# MB9BF51xS register map
File version: 1.8
CPU: 
Registers are 16-bit, read-write, reset 0x0 unless marked. A register's access mark holds for its fields unless they carry their own. Offsets are from the block's base; [hi:lo] are bit positions; {n}, {i} and the like mark numbered series.

## QPRC0 — Quadrature Position/Revolution Counter 0
Base 0x40026000
Same registers: QPRC1 0x40026040, QPRC2 0x40026080
0x00 QPCR — QPRC Position Count Register
0x04 QRCR — QPRC Revolution Count Register
0x08 QPCCR — QPRC Position Counter Compare Register
0x0C QPRCR — QPRC Position and Revolution Counter Compare Register
0x10 QMPR reset 0xFFFF — QPRC Maximum Position Register
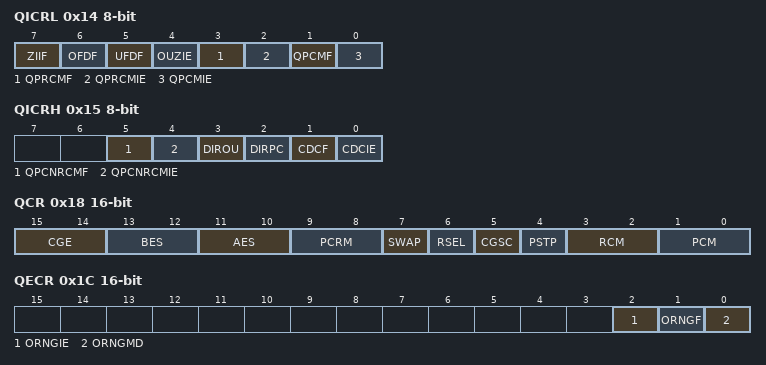
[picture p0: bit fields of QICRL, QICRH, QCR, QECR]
0x14 QICRL 8-bit — Low-Order Bytes of QPRC Interrupt Control Register
  [7] ZIIF — Zero index interrupt request flag bit
  [6] OFDF — Overflow interrupt request flag bit
  [5] UFDF — Underflow interrupt request flag bit
  [4] OUZIE — "Overflow, underflow, or zero index interrupt enable bit"
  [3] QPRCMF — PC and RC match interrupt request flag bit
  [2] QPRCMIE — PC and RC match interrupt enable bit
  [1] QPCMF — PC match interrupt request flag bit
  [0] QPCMIE — PC match interrupt enable bit
0x15 QICRH 8-bit — High-Order Bytes of QPRC Interrupt Control Register
  [5] QPCNRCMF — PC match and RC match interrupt request flag bit
  [4] QPCNRCMIE — PC match and RC match interrupt enable bit
  [3] DIROU ro — Last position counter flow direction bit
  [2] DIRPC ro — Last position counter direction bit
  [1] CDCF — Count inversion interrupt request flag bit
  [0] CDCIE — Count inversion interrupt enable bit
0x18 QCR — QPRC Control Register
  [15:14] CGE — Detection edge selection bits
  [13:12] BES — BIN detection edge selection bits
  [11:10] AES — AIN detection edge selection bits
  [9:8] PCRM — Position counter reset mask bits
  [7] SWAP — Swap bit
  [6] RSEL — Register function selection bit
  [5] CGSC — Count clear or gate selection bit
  [4] PSTP — Position counter stop bit
  [3:2] RCM — Revolution counter mode bits
  [1:0] PCM — Position counter mode bits
0x1C QECR — QPRC Extension Control Register
  [2] ORNGIE — Outrange interrupt enable bit
  [1] ORNGF — Outrange interrupt request flag bit
  [0] ORNGMD — Outrange mode selection bit
0x3C QRCRR — Quad counter rotation count Register
0x3E QPCRR — Quad counter position count Register

## WC — Watch Counter
Base 0x4003A000
0x00 WCRD 8-bit ro — Watch Counter Read Register
  [5:0] CTR — counter value
0x01 WCRL 8-bit — Watch Counter Reload Register
  [5:0] RLC — reload value
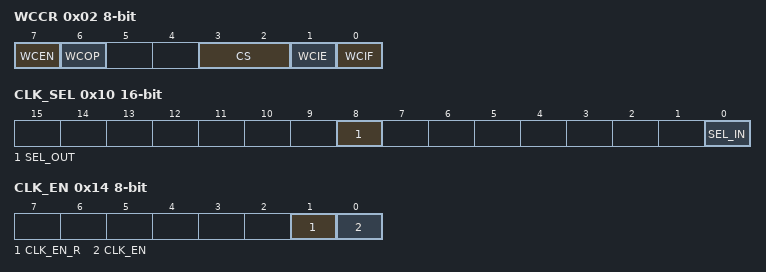
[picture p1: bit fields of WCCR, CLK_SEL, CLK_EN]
0x02 WCCR 8-bit — Watch Counter Control Register
  [7] WCEN — Watch counter operation enable bit
  [6] WCOP ro — Watch counter operating state flag
  [3:2] CS — Count clock select bits
  [1] WCIE — Interrupt request enable bit
  [0] WCIF — Interrupt request flag bit
0x10 CLK_SEL — Clock Selection Register
  [8] SEL_OUT — Output clock selection bit
  [0] SEL_IN — Input clock selection bit
0x14 CLK_EN 8-bit — Division Clock Enable Register
  [1] CLK_EN_R — Division clock enable read bit
  [0] CLK_EN — Division clock enable bit

## EXTI — External Interrupt and NMI Control
Base 0x40030000
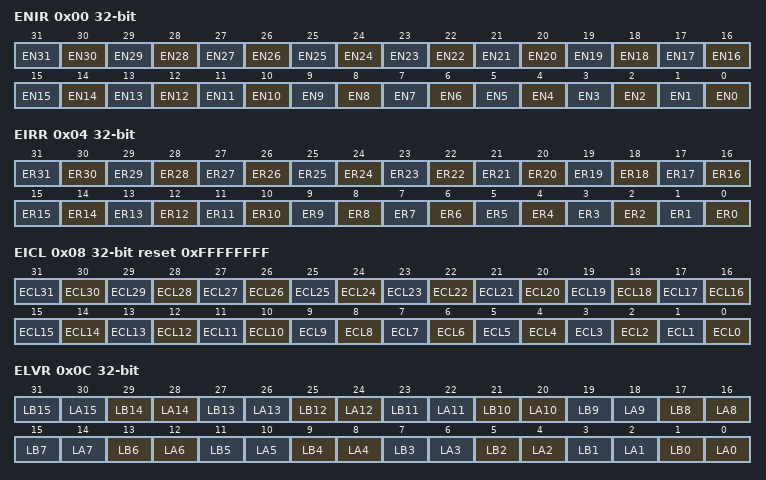
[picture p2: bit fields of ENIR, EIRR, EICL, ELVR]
0x00 ENIR 32-bit — Enable Interrupt Request Register
  [n] EN{n} (n=0..31) — Bit{n} of ENIR
0x04 EIRR 32-bit ro reset not defined — External Interrupt Request Register
  [n] ER{n} (n=0..31) — Bit{n} of EIRR
0x08 EICL 32-bit reset 0xFFFFFFFF — External Interrupt Clear Register
  [n] ECL{n} (n=0..31) — Bit{n} of EICL
0x0C ELVR 32-bit — External Interrupt Level Register
  [2n+1] LB{n} (n=0..15) — Bit{2n+1} of ELVR
  [2n] LA{n} (n=0..15) — Bit{2n} of ELVR
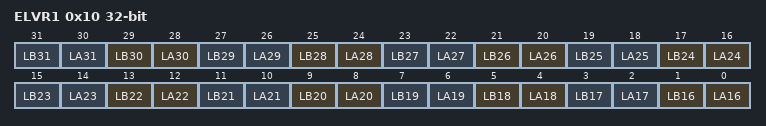
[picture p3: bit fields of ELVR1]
0x10 ELVR1 32-bit — External Interrupt Level Register 1
  [2n-31] LB{n} (n=16..31) — Bit{2n-31} of ELVR1
  [2n-32] LA{n} (n=16..31) — Bit{2n-32} of ELVR1
0x14 NMIRR 8-bit ro — Non Maskable Interrupt Request Register
  [0] NR — NMI interrupt request detection bit
0x18 NMICL 8-bit reset 0x1 — Non Maskable Interrupt Clear Register
  [0] NCL — NMI interrupt cause clear bit

## LVD — Low-voltage Detection
Base 0x40035000
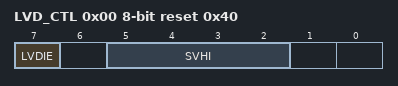
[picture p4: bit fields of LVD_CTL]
0x00 LVD_CTL 8-bit reset 0x40 — Low-voltage Detection Voltage Control Register
  [7] LVDIE — Low-voltage detection interrupt enable bit
  [5:2] SVHI — Low-voltage detection interrupt voltage setting bits
0x04 LVD_STR 8-bit ro — Low-voltage Detection Interrupt Register
  [7] LVDIR — Low-voltage detection interrupt bit
0x08 LVD_CLR 8-bit reset 0x80 — Low-voltage Detection Interrupt Clear Register
  [7] LVDCL — Low-voltage detection interrupt clear bit
0x0C LVD_RLR 32-bit reset 0x1 — Low-voltage Detection Voltage Protection Register
  [31:0] LVDLCK — Low-voltage Detection Voltage Control Register protection bits
0x10 LVD_STR2 8-bit ro reset 0x40 — Low-voltage Detection Circuit Status Register
  [7] LVDIRDY — Low-voltage detection interrupt status flag
